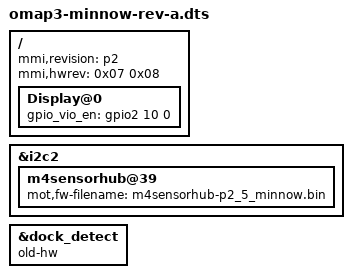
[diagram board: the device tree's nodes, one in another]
/*
 * Copyright (C) 2014 Motorola Mobility LLC
 *
 * This program is free software; you can redistribute it and/or modify
 * it under the terms of the GNU General Public License version 2 as
 * published by the Free Software Foundation.
 */
/dts-v1/;

/include/ "omap3-minnow.dtsi"

/ {
	mmi,revision = "p2";
	mmi,hwrev = <
		0x07   /* Minnow P2-5 portable (Rev A) */
		0x08   /* Minnow P2-5 wingboard (issue 04) */
	>;

	Display@0 {
		gpio_vio_en = <&gpio2 10 0>;    /* VDDIO gpio-42 */
	};

};

&i2c2{
	m4sensorhub@39 {
		mot,fw-filename = "m4sensorhub-p2_5_minnow.bin";
	};
};

&dock_detect {
	old-hw;
};
